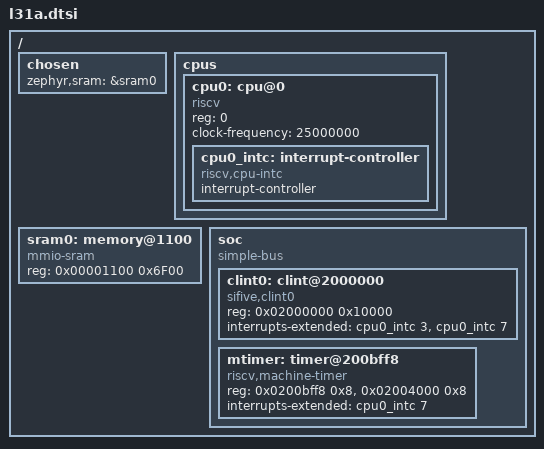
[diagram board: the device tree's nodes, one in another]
/*
 * Copyright (c) 2026 by Georgij Michaliutin
 *
 * SPDX-License-Identifier: Apache-2.0
 */

/dts-v1/;

#include <skeleton.dtsi>
#include <freq.h>
#include <mem.h>

/ {
	#address-cells = <1>;
	#size-cells = <1>;

	chosen {
		zephyr,sram = &sram0;
	};

	cpus {
		#address-cells = <1>;
		#size-cells = <0>;

		cpu0: cpu@0 {
			device_type = "cpu";
			compatible = "riscv";
			reg = <0>;
            status = "okay";

            /* This clock is dependent on HDL Clock divider */ 
			clock-frequency = <25000000>;

			cpu0_intc: interrupt-controller {
				compatible = "riscv,cpu-intc";
				#interrupt-cells = <1>;
				interrupt-controller;
			};
		};
	};

	/*
	 * BRAM: 16384 x 32-bit = 64 KB (0x0000_0000 – 0x0000_FFFF).
	 * Currently Zephyr uses lower 32 KB (0x0000 – 0x7FFF).
	 * Zephyr starts at 0x1100, after debug and NMI reserved regions.
	 * Usable: 0x8000 - 0x1100 = 0x6F00 (28,416 bytes).
	 */
	sram0: memory@1100 {
		device_type = "memory";
		compatible = "mmio-sram";
		reg = <0x00001100 0x6F00>;
	};

	soc {
		#address-cells = <1>;
		#size-cells = <1>;
        compatible = "simple-bus";
		ranges;

		/*
		 * CLINT: machine software interrupt (MSIP) and machine timer (MTIP).
		 */
		clint0: clint@2000000 {
			compatible = "sifive,clint0";
			reg = <0x02000000 0x10000>;
			interrupts-extended = <&cpu0_intc 3>, <&cpu0_intc 7>;
		};
		
        mtimer: timer@200bff8 {
          compatible = "riscv,machine-timer";
          reg = <0x0200bff8 0x8>,
                <0x02004000 0x8>;
          reg-names = "mtime", "mtimecmp";
          interrupts-extended = <&cpu0_intc 7>;
        };

		/* TODO: GPIO, check with driver, no interrupt on LEDs

		gpio0: gpio@3000000 {
			compatible = "codasip,ahb-gpio";
			reg = <0x03000000 0x4>;
			gpio-controller;
			#gpio-cells = <2>;
			ngpios = <16>;
			status = "okay";
		};
		*/
	};
};
